# MINI51DE_v1 register map
File version: 1.0
Registers are 32-bit, read-write, reset 0x0 unless marked. A register's access mark holds for its fields unless they carry their own. Offsets are from the block's base; [hi:lo] are bit positions; {n}, {i} and the like mark numbered series; 'fields as' and 'values as' point back to an identical list.

## GP — GPIO Register Map
Base 0x50004000
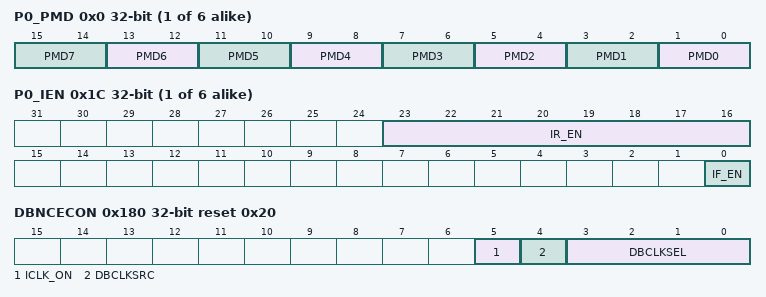
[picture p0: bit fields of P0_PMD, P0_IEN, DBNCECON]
{0x0+0x40*i} P{i}_PMD (reset mask 0xFFFF0000) (i=0..5) — P{i} I/O Mode Control
  [all] fields
    0=Px.n is in Input mode; 1=Px.n is in Push-pull Output mode; 2=Px.n is in Open-drain Output mode; 3=Px.n is in Quasi-bidirectional mode
  [2n+1:2n] PMD{n} (n=0..7) — Port 0-5 I/O Pin [N] Mode Control. Determine each I/O mode of Px.n pin. Default mode is controlled by CIOINI (CONFIG0[10]). Note2: P0_PMD[7:4] are reserved. P1_PMD[15:12], [3:2] are reserved. P2_PMD[15:14], [3:0] are reserved. P3_PMD[15:14], [7:6] are reserved. P4_PMD[11:0] are reserved. P5_PMD[15:12] are reserved.
{0x4+0x40*i} P{i}_OFFD (i=0..5) — P{i} Digital Input Path Disable Control
  [23:16] OFFD — Port 0-5 Pin [N] Digital Input Path Disable Control
    0=Px.n digital input path Enabled; 1=Px.n digital input path Disabled (digital input tied to low)
{0x8+0x40*i} P{i}_DOUT reset 0xF3 (i=0..5) — P{i} Data Output Value
  [7:0] DOUT — Port 0-5 Pin [N] Output Value. Each of these bits controls the status of a Px.n pin when the Px.n is configured as Push-pull output, Open-drain output and Quasi-bidirectional mode. Note2: P0_DOUT[3:2] are reserved. P1_DOUT[7:6], [1] are reserved. P2_DOUT[7], [1:0] are reserved. P3_DOUT[7], [3] are reserved. P4_DOUT[5:0] are reserved. P5_DOUT[7:6] are reserved.
    0=Px.n will drive Low if the Px.n pin is configured as Push-pull output, Open-drain output or Quasi-bidirectional mode; 1=Px.n will drive High if the Px.n pin is configured as Push-pull output or Quasi-bidirectional mode
{0xC+0x40*i} P{i}_DMASK (i=0..5) — P{i} Data Output Write Mask
  [7:0] DMASK — Port 0-5 Pin [N] Data Output Write Mask. These bits are used to protect the corresponding Px_DOUT[n] bit. When the DMASK[n] bit is set to 1, the corresponding Px_DOUT[n] bit is protected. If the write signal is masked, writing data to the protect bit is ignored. Note2: This function only protects the corresponding Px_DOUT[n] bit, and will not protect the corresponding Pxn_PDIO bit. Note3: P0_DMASK[3:2] are reserved. P1_DMASK[7:6], [1] are reserved. P2_DMASK[7], [1:0] are reserved. P3_DMASK[7], [3] are reserved. P4_DMASK[5:0] are reserved. P5_DMASK[7:6] are reserved.
    0=Corresponding Px_DOUT[n] bit can be updated; 1=Corresponding Px_DOUT[n] bit is protected
{0x10+0x40*i} P{i}_PIN ro (reset mask 0xFFFFFF00) (i=0..5) — P{i} Pin Value
  [7:0] PIN — Port 0-5 Pin [N] Pin Value. Each bit of the register reflects the actual status of the respective Px.n pin. If the bit is 1, it indicates the corresponding pin status is high; else the pin status is low. Note2: P0_PIN[3:2] are reserved. P1_PIN[7:6], [1] are reserved. P2_PIN[7], [1:0] are reserved. P3_PIN[7], [3] are reserved. P4_PIN[5:0] are reserved. P5_PIN[7:6] are reserved.
{0x14+0x40*i} P{i}_DBEN (i=0..5) — P{i} De-bounce Enable Control
  [7:0] DBEN — Port 0-5 Pin [N] Input Signal De-bounce Enable Control. DBEN[n] bit is used to enable the de-bounce function for each corresponding bit. If the input signal pulse width cannot be sampled by continuous two de-bounce sample cycle, the input signal transition is seen as the signal bounce and will not trigger the interrupt. The de-bounce clock source is controlled by DBNCECON[4], one de-bounce sample cycle period is controlled by DBNCECON[3:0]. Note2: If Px.n pin is chosen as Power-down wake-up source, user should be disable the de-bounce function before entering Power-down mode to avoid the second interrupt event occurred after system woken up caused by the Px.n de-bounce function. Note3: P0_DBEN[3:2] are reserved. P1_DBEN[7:6], [1] are reserved. P2_DBEN[7], [1:0] are reserved. P3_DBEN[7], [3] are reserved. P4_DBEN[5:0] are reserved. P5_DBEN[7:6] are reserved.
    0=Px.n de-bounce function Disabled; 1=Px.n de-bounce function Enabled
{0x18+0x40*i} P{i}_IMD (i=0..5) — P{i} Interrupt Mode Control
  [7:0] IMD — Port 0-5 Pin [N] Edge Or Level Detection Interrupt Mode Control. IMD[n] bit is used to control the triggered interrupt is by level trigger or by edge trigger. If the interrupt is by edge trigger, the trigger source can be controlled by de-bounce. If the interrupt is by level trigger, the input source is sampled by one HCLK clock and generates the interrupt. Note2: P0_IMD[3:2] are reserved. P1_IMD[7:6], [1] are reserved. P2_IMD[7], [1:0] are reserved. P3_IMD[7], [3] are reserved. P4_IMD[5:0] are reserved. P5_IMD[7:6] are reserved.
    0=Edge trigger interrupt; 1=Level trigger interrupt
{0x1C+0x40*i} P{i}_IEN (i=0..5) — P{i} Interrupt Enable Control
  [23:16] IR_EN — Port 0-5 Pin [N] Interrupt Enabled By Input Rising Edge Or Input Level High. IR_EN[n] bit is used to enable the interrupt for each of the corresponding input Px.n pin. Set bit to 1 also enable the pin wake-up function. When setting the IR_EN[n] bit to 1: If the interrupt is level trigger (IMD[n] is 1), the input Px.n pin will generate the interrupt while this pin state is at high level. If the interrupt is edge trigger (IMD[n] is 0), the input Px.n pin will generate the interrupt while this pin state changed from low to high.
    0=Px.n level high or low to high interrupt Disabled; 1=Px.n level high or low to high interrupt Enabled
  [0] IF_EN — Port 0-5 Pin [N] Interrupt Enabled By Input Falling Edge Or Input Level Low. IF_EN[n] is used to enable the interrupt for each of the corresponding input Px.n pin. Set bit to 1 also enable the pin wake-up function. When setting the IF_EB[n] bit to 1: If the interrupt is level trigger (IMD[n] is 1), the input Px.n pin will generate the interrupt while this pin state is at low level. If the interrupt is edge mode trigger (IMD[n] is 0), the input Px.n pin will generate the interrupt while this pin state changed from high to low. Note2: P0_IEN[19:18], [3:2] are reserved. P1_IEN[23:22], [17], [7:6], [1] are reserved. P2_IEN[23], [17:16], [7], [1:0] are reserved. P3_IEN[23], [19], [7], [3] are reserved. P4_IEN[21:16], [5:0] are reserved. P5_IEN[23:22], [7:6] are reserved.
    0=Px.n low level or high to low interrupt Disabled; 1=Px.n low level or high to low interrupt Enabled
{0x20+0x40*i} P{i}_ISRC (i=0..5) — P{i} Interrupt Source Flag
  [7:0] ISRC — Port 0-5 Pin [N] Interrupt Source Flag. Write : Note2: P0_ISRC[3:2] are reserved. P1_ISRC[7:6], [1] are reserved. P2_ISRC[7], [1:0] are reserved. P3_ISRC[7], [3] are reserved. P4_ISRC[5:0] are reserved. P5_ISRC[7:6] are reserved.
    0=No action. No interrupt at Px.n; 1=Clear the corresponding pending interrupt. Px.n generates an interrupt
0x180 DBNCECON reset 0x20 — Interrupt De-bounce Control
  [5] ICLK_ON — Interrupt Clock On Mode. Note: It is recommended to turn off this bit to save system power if no special application concern.
    0=Edge detection circuit is active only if I/O pin corresponding Px_IEN bit is set to 1; 1=All I/O pins edge detection circuit is always active after reset
  [4] DBCLKSRC — De-bounce Counter Clock Source Selection
    0=De-bounce counter clock source is the HCLK; 1=De-bounce counter clock source is the 10 kHz internal low speed oscillator
  [3:0] DBCLKSEL — De-bounce Sampling Cycle Selection
0x200 P00_PDIO reset 0x1 — GPIO P0.0 Pin Data Input/Output
  [0] P_PDIO — GPIO Px.N Pin Data Iutput/Output. Writing this bit can control one GPIO pin output value. Note2: The writing operation will not be affected by register Px_DMASK[n].
    0=Corresponding GPIO pin set to low. Corresponding GPIO pin status is low; 1=Corresponding GPIO pin set to high. Corresponding GPIO pin status is high
0x204 P01_PDIO reset 0x1 — GPIO P0.1 Pin Data Input/Output
  fields as P00_PDIO
0x210 P04_PDIO reset 0x1 — GPIO P0.4 Pin Data Input/Output
  fields as P00_PDIO
0x214 P05_PDIO reset 0x1 — GPIO P0.5 Pin Data Input/Output
  fields as P00_PDIO
0x218 P06_PDIO reset 0x1 — GPIO P0.6 Pin Data Input/Output
  fields as P00_PDIO
0x21C P07_PDIO reset 0x1 — GPIO P0.7 Pin Data Input/Output
  fields as P00_PDIO
0x220 P10_PDIO reset 0x1 — GPIO P1.0 Pin Data Input/Output
  fields as P00_PDIO
0x228 P12_PDIO reset 0x1 — GPIO P1.2 Pin Data Input/Output
  fields as P00_PDIO
0x22C P13_PDIO reset 0x1 — GPIO P1.3 Pin Data Input/Output
  fields as P00_PDIO
0x230 P14_PDIO reset 0x1 — GPIO P1.4 Pin Data Input/Output
  fields as P00_PDIO
0x234 P15_PDIO reset 0x1 — GPIO P1.5 Pin Data Input/Output
  fields as P00_PDIO
0x248 P22_PDIO reset 0x1 — GPIO P2.2 Pin Data Input/Output
  fields as P00_PDIO
0x24C P23_PDIO reset 0x1 — GPIO P2.3 Pin Data Input/Output
  fields as P00_PDIO
0x250 P24_PDIO reset 0x1 — GPIO P2.4 Pin Data Input/Output
  fields as P00_PDIO
0x254 P25_PDIO reset 0x1 — GPIO P2.5 Pin Data Input/Output
  fields as P00_PDIO
0x258 P26_PDIO reset 0x1 — GPIO P2.6 Pin Data Input/Output
  fields as P00_PDIO
0x260 P30_PDIO reset 0x1 — GPIO P3.0 Pin Data Input/Output
  fields as P00_PDIO
0x264 P31_PDIO reset 0x1 — GPIO P3.1 Pin Data Input/Output
  fields as P00_PDIO
0x268 P32_PDIO reset 0x1 — GPIO P3.2 Pin Data Input/Output
  fields as P00_PDIO
0x270 P34_PDIO reset 0x1 — GPIO P3.4 Pin Data Input/Output
  fields as P00_PDIO
0x274 P35_PDIO reset 0x1 — GPIO P3.5 Pin Data Input/Output
  fields as P00_PDIO
0x278 P36_PDIO reset 0x1 — GPIO P3.6 Pin Data Input/Output
  fields as P00_PDIO
0x298 P46_PDIO reset 0x1 — GPIO P4.6 Pin Data Input/Output
  fields as P00_PDIO
0x29C P47_PDIO reset 0x1 — GPIO P4.7 Pin Data Input/Output
  fields as P00_PDIO
0x2A0 P50_PDIO reset 0x1 — GPIO P5.0 Pin Data Input/Output
  fields as P00_PDIO
0x2A4 P51_PDIO reset 0x1 — GPIO P5.1 Pin Data Input/Output
  fields as P00_PDIO
0x2A8 P52_PDIO reset 0x1 — GPIO P5.2 Pin Data Input/Output
  fields as P00_PDIO
0x2AC P53_PDIO reset 0x1 — GPIO P5.3 Pin Data Input/Output
  fields as P00_PDIO
0x2B0 P54_PDIO reset 0x1 — GPIO P5.4 Pin Data Input/Output
  fields as P00_PDIO
0x2B4 P55_PDIO reset 0x1 — GPIO P5.5 Pin Data Input/Output
  fields as P00_PDIO
